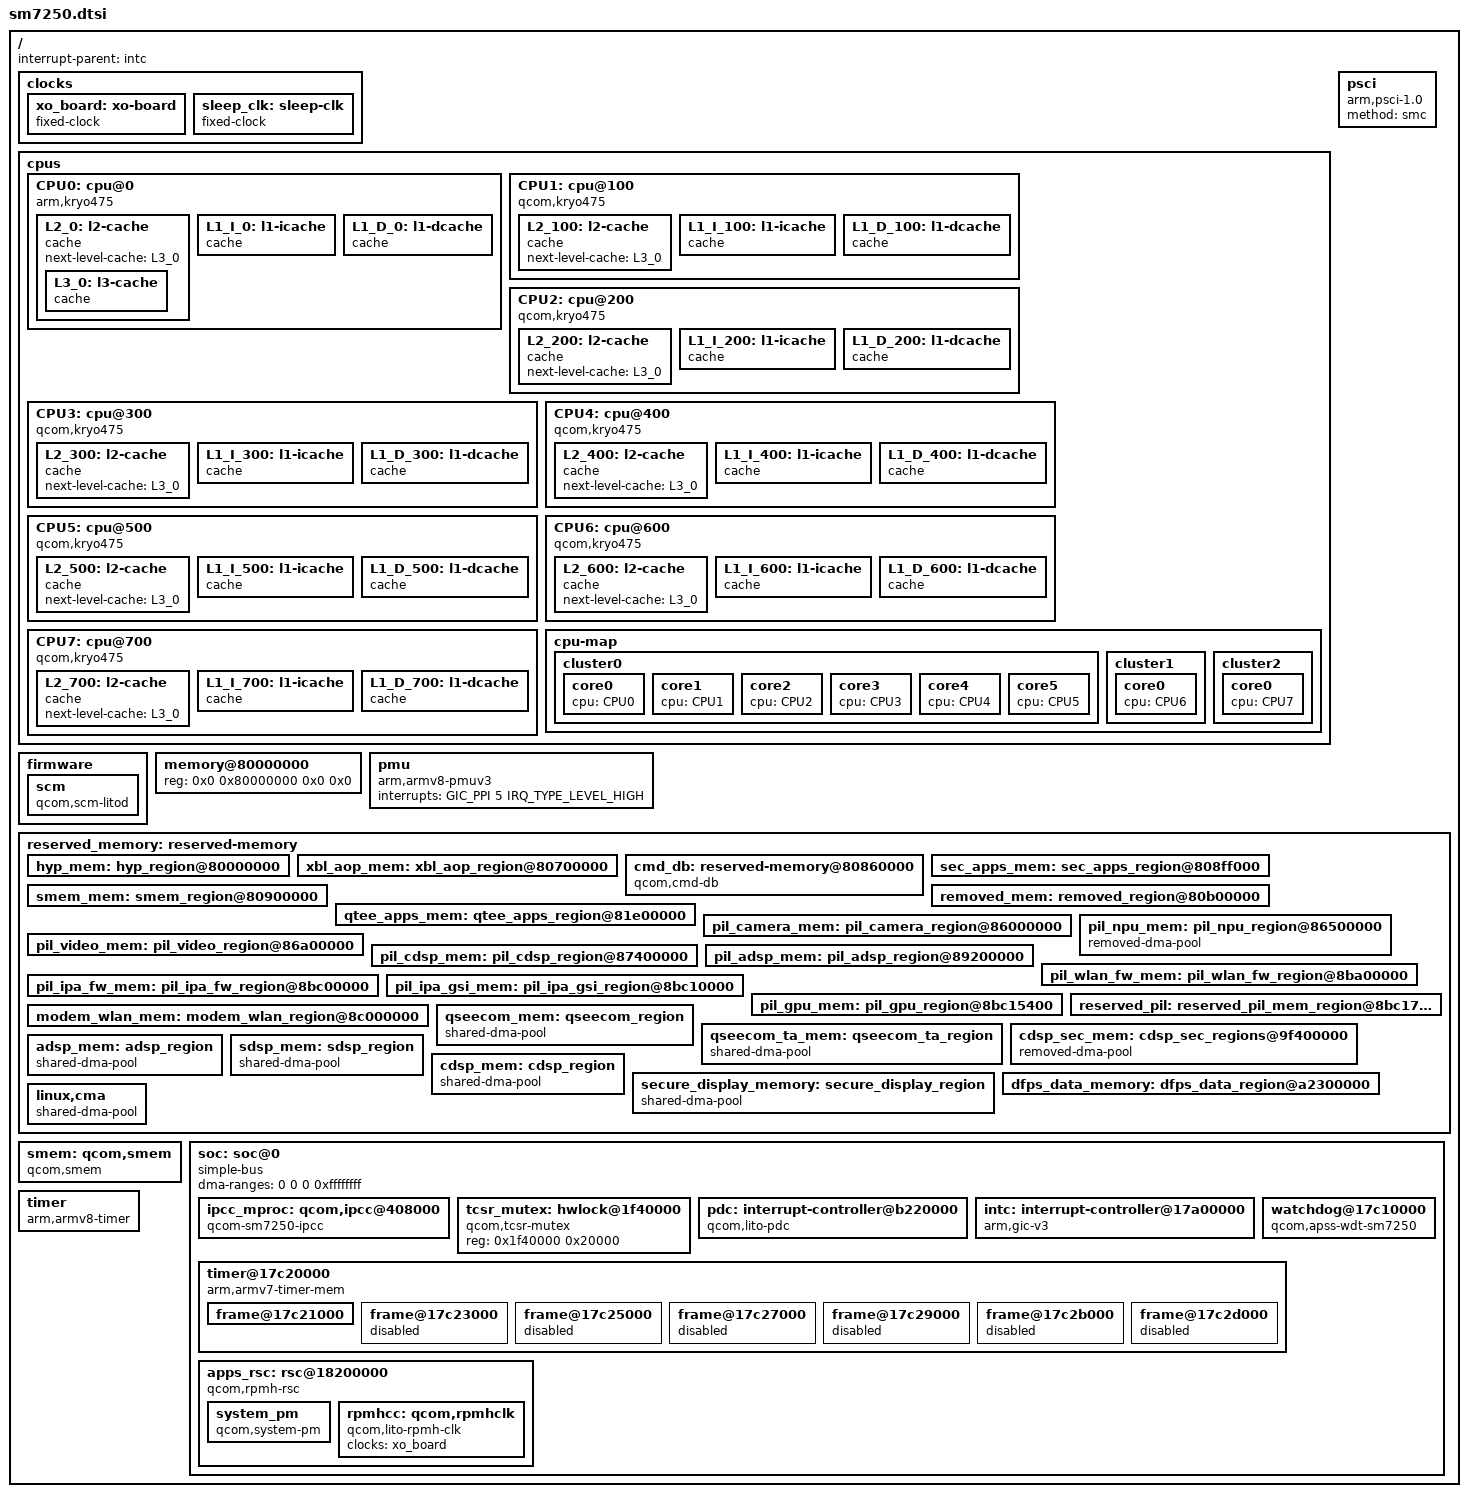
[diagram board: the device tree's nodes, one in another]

// SPDX-License-Identifier: BSD-3-Clause
/*
 */

#include <dt-bindings/clock/qcom,gcc-sm7250.h>
#include <dt-bindings/clock/qcom,rpmh.h>
#include <dt-bindings/gpio/gpio.h>
#include <dt-bindings/interrupt-controller/arm-gic.h>
#include <dt-bindings/mailbox/qcom-ipcc.h>
#include <dt-bindings/soc/qcom,rpmh-rsc.h>

/ {
	interrupt-parent = <&intc>;
	#address-cells = <2>;
	#size-cells = <2>;
	clocks {
		xo_board: xo-board {
			compatible = "fixed-clock";
			clock-frequency = <38400000>;
			clock-output-names = "xo_board";
			#clock-cells = <0>;
		};

		sleep_clk: sleep-clk {
			compatible = "fixed-clock";
			clock-output-names = "chip_sleep_clk";
			clock-frequency = <32000>;
			#clock-cells = <0>;
		};
	};
	cpus {
		#address-cells = <2>;
		#size-cells = <0>;

		CPU0: cpu@0 {
			device_type = "cpu";
			compatible = "arm,kryo475";
			reg = <0x0 0x0>;
			enable-method = "psci";
			capacity-dmips-mhz = <488>;
			dynamic-power-coefficient = <166>;
			next-level-cache = <&L2_0>;
			#cooling-cells = <2>;
			L2_0: l2-cache {
			      compatible = "cache";
			      next-level-cache = <&L3_0>;
				L3_0: l3-cache {
				      compatible = "cache";
				};
			};

			L1_I_0: l1-icache {
				compatible = "cache";
			};

			L1_D_0: l1-dcache {
				compatible = "cache";
			};

		};

		CPU1: cpu@100 {
			device_type = "cpu";
			compatible = "qcom,kryo475";
			reg = <0x0 0x100>;
			enable-method = "psci";
			capacity-dmips-mhz = <488>;
			dynamic-power-coefficient = <166>;
			next-level-cache = <&L2_100>;
			L2_100: l2-cache {
				compatible = "cache";
				next-level-cache = <&L3_0>;
			};

			L1_I_100: l1-icache {
				compatible = "cache";
			};

			L1_D_100: l1-dcache {
				compatible = "cache";
			};

		};

		CPU2: cpu@200 {
			device_type = "cpu";
			compatible = "qcom,kryo475";
			reg = <0x0 0x200>;
			enable-method = "psci";
			capacity-dmips-mhz = <488>;
			dynamic-power-coefficient = <166>;
			next-level-cache = <&L2_200>;
			L2_200: l2-cache {
				compatible = "cache";
				next-level-cache = <&L3_0>;
			};

			L1_I_200: l1-icache {
				compatible = "cache";
			};

			L1_D_200: l1-dcache {
				compatible = "cache";
			};

		};

		CPU3: cpu@300 {
			device_type = "cpu";
			compatible = "qcom,kryo475";
			reg = <0x0 0x300>;
			enable-method = "psci";
			capacity-dmips-mhz = <488>;
			dynamic-power-coefficient = <166>;
			next-level-cache = <&L2_300>;
			L2_300: l2-cache {
				compatible = "cache";
				next-level-cache = <&L3_0>;
			};

			L1_I_300: l1-icache {
				compatible = "cache";
			};

			L1_D_300: l1-dcache {
				compatible = "cache";
			};

		};

		CPU4: cpu@400 {
			device_type = "cpu";
			compatible = "qcom,kryo475";
			reg = <0x0 0x400>;
			enable-method = "psci";
			capacity-dmips-mhz = <488>;
			dynamic-power-coefficient = <166>;
			next-level-cache = <&L2_400>;
			L2_400: l2-cache {
				compatible = "cache";
				next-level-cache = <&L3_0>;
			};

			L1_I_400: l1-icache {
				compatible = "cache";
			};

			L1_D_400: l1-dcache {
				compatible = "cache";
			};
		};

		CPU5: cpu@500 {
			device_type = "cpu";
			compatible = "qcom,kryo475";
			reg = <0x0 0x500>;
			enable-method = "psci";
			capacity-dmips-mhz = <488>;
			dynamic-power-coefficient = <166>;
			next-level-cache = <&L2_500>;
			L2_500: l2-cache {
				compatible = "cache";
				next-level-cache = <&L3_0>;
			};

			L1_I_500: l1-icache {
				compatible = "cache";
			};

			L1_D_500: l1-dcache {
				compatible = "cache";
			};
		};

		CPU6: cpu@600 {
			device_type = "cpu";
			compatible = "qcom,kryo475";
			reg = <0x0 0x600>;
			enable-method = "psci";
			capacity-dmips-mhz = <1024>;
			dynamic-power-coefficient = <393>;
			next-level-cache = <&L2_600>;
			#cooling-cells = <2>;
			L2_600: l2-cache {
				compatible = "cache";
				next-level-cache = <&L3_0>;
			};

			L1_I_600: l1-icache {
				compatible = "cache";
			};

			L1_D_600: l1-dcache {
				compatible = "cache";
			};

		};

		CPU7: cpu@700 {
			device_type = "cpu";
			compatible = "qcom,kryo475";
			reg = <0x0 0x700>;
			enable-method = "psci";
			capacity-dmips-mhz = <1024>;
			dynamic-power-coefficient = <428>;
			next-level-cache = <&L2_700>;
			#cooling-cells = <2>;
			L2_700: l2-cache {
				compatible = "cache";
				next-level-cache = <&L3_0>;
			};

			L1_I_700: l1-icache {
				compatible = "cache";
			};

			L1_D_700: l1-dcache {
				compatible = "cache";
			};
		};
		cpu-map {
			cluster0 {
				core0 {
					cpu = <&CPU0>;
				};

				core1 {
					cpu = <&CPU1>;
				};

				core2 {
					cpu = <&CPU2>;
				};

				core3 {
					cpu = <&CPU3>;
				};

				core4 {
					cpu = <&CPU4>;
				};

				core5 {
					cpu = <&CPU5>;
				};
			};

			cluster1 {
				core0 {
					cpu = <&CPU6>;
				};
			};

			cluster2 {
				core0 {
					cpu = <&CPU7>;
				};
			};
		};
	};
	firmware {
		scm: scm {
			compatible = "qcom,scm-litod", "qcom,scm";
			#reset-cells = <1>;
		};
	};
	memory@80000000 {
		device_type = "memory";
		/* We expect the bootloader to fill in the size */
		reg = <0x0 0x80000000 0x0 0x0>;
	};
	pmu {
                compatible = "arm,armv8-pmuv3";
                interrupts = <GIC_PPI 5 IRQ_TYPE_LEVEL_HIGH>;
        };
	psci {
	compatible = "arm,psci-1.0";
	method = "smc";
	};
	reserved_memory: reserved-memory {
		#address-cells = <2>;
		#size-cells = <2>;
		ranges;

		hyp_mem: hyp_region@80000000 {
			reg = <0x0 0x80000000 0x0 0x600000>;
			no-map;
		};

		xbl_aop_mem: xbl_aop_region@80700000 {
			reg = <0x0 0x80700000 0x0 0x160000>;
			no-map;
		};

		cmd_db: reserved-memory@80860000 {
			compatible = "qcom,cmd-db";
			reg = <0x0 0x80860000 0x0 0x20000>;
			no-map;
		};

		sec_apps_mem: sec_apps_region@808ff000 {
			reg = <0x0 0x808ff000 0x0 0x1000>;
			no-map;
		};

		smem_mem: smem_region@80900000 {
			reg = <0x0 0x80900000 0x0 0x200000>;
			no-map;
		};

		removed_mem: removed_region@80b00000 {
			reg = <0x0 0x80b00000 0x0 0x1300000>;
			no-map;
		};

		qtee_apps_mem: qtee_apps_region@81e00000 {
			reg = <0x0 0x81e00000 0x0 0x4200000>;
			no-map;
		};

		pil_camera_mem: pil_camera_region@86000000 {
			reg = <0x0 0x86000000 0x0 0x500000>;
			no-map;
		};

		pil_npu_mem: pil_npu_region@86500000 {
			compatible = "removed-dma-pool";
			no-map;
			reg = <0x0 0x86500000 0x0 0x500000>;
		};

		pil_video_mem: pil_video_region@86a00000 {
			reg = <0x0 0x86a00000 0x0 0x500000>;
			no-map;
		};

		pil_cdsp_mem: pil_cdsp_region@87400000 {
			reg = <0x0 0x87400000 0x0 0x1e00000>;
			no-map;
		};

		pil_adsp_mem: pil_adsp_region@89200000 {
			reg = <0x0 0x89200000 0x0 0x2800000>;
			no-map;
		};

		pil_wlan_fw_mem: pil_wlan_fw_region@8ba00000 {
			reg = <0x0 0x8ba00000 0x0 0x200000>;
			no-map;
		};

		pil_ipa_fw_mem: pil_ipa_fw_region@8bc00000 {
			reg = <0x0 0x8bc00000 0x0 0x10000>;
			no-map;
		};

		pil_ipa_gsi_mem: pil_ipa_gsi_region@8bc10000 {
			reg = <0x0 0x8bc10000 0x0 0x5400>;
			no-map;
		};

		pil_gpu_mem: pil_gpu_region@8bc15400 {
			reg = <0x0 0x8bc15400 0x0 0x2000>;
			no-map;
		};

		reserved_pil: reserved_pil_mem_region@8bc17400 {
			reg = <0x0 0x8bc17400 0x0 0x3e8c00>;
			no-map;
		};

		modem_wlan_mem: modem_wlan_region@8c000000 {
			reg = <0x0 0x8c000000 0x0 0xf800000>;
			no-map;
		};

		qseecom_mem: qseecom_region {
			compatible = "shared-dma-pool";
			alloc-ranges = <0x0 0x00000000 0x0 0xffffffff>;
			reusable;
			alignment = <0x0 0x400000>;
			size = <0x0 0x1400000>;
		};

		qseecom_ta_mem: qseecom_ta_region {
			compatible = "shared-dma-pool";
			alloc-ranges = <0x0 0x00000000 0x0 0xffffffff>;
			reusable;
			alignment = <0x0 0x400000>;
			size = <0x0 0x1000000>;
		};

		cdsp_sec_mem: cdsp_sec_regions@9f400000 {
			compatible = "removed-dma-pool";
			no-map;
			reg = <0x0 0x9f400000 0x0 0xc00000>;
		};

		adsp_mem: adsp_region {
			compatible = "shared-dma-pool";
			alloc-ranges = <0x0 0x00000000 0x0 0xffffffff>;
			reusable;
			alignment = <0x0 0x400000>;
			size = <0x0 0xC00000>;
		};

		sdsp_mem: sdsp_region {
			compatible = "shared-dma-pool";
			alloc-ranges = <0x0 0x00000000 0x0 0xffffffff>;
			reusable;
			alignment = <0x0 0x400000>;
			size = <0x0 0x400000>;
		};

		cdsp_mem: cdsp_region {
			compatible = "shared-dma-pool";
			alloc-ranges = <0x0 0x00000000 0x0 0xffffffff>;
			reusable;
			alignment = <0x0 0x400000>;
			size = <0x0 0x400000>;
		};

		secure_display_memory: secure_display_region { /* Secure UI */
			compatible = "shared-dma-pool";
			alloc-ranges = <0x0 0x00000000 0x0 0xffffffff>;
			reusable;
			alignment = <0x0 0x400000>;
			size = <0x0 0xA000000>;
		};

		dfps_data_memory: dfps_data_region@a2300000 {
			reg = <0x0 0xa2300000 0x0 0x0100000>;
			label = "dfps_data_region";
		};

		/* global autoconfigured region for contiguous allocations */
		linux,cma {
			compatible = "shared-dma-pool";
			alloc-ranges = <0x0 0x00000000 0x0 0xffffffff>;
			reusable;
			alignment = <0x0 0x400000>;
			size = <0x0 0x2000000>;
			linux,cma-default;
		};

	};
	smem: qcom,smem {
		compatible = "qcom,smem";
		memory-region = <&smem_mem>;
		hwlocks = <&tcsr_mutex 3>;
	};
	soc: soc@0 {
		#address-cells = <1>;
		#size-cells = <1>;
		ranges = <0 0 0 0xffffffff>;
		dma-ranges = <0 0 0 0xffffffff>;
		compatible = "simple-bus";

		ipcc_mproc: qcom,ipcc@408000 {
			compatible = "qcom-sm7250-ipcc", "qcom,ipcc";
			reg = <0x408000 0x1000>;
			interrupts = <GIC_SPI 229 IRQ_TYPE_LEVEL_HIGH>;
			interrupt-controller;
			#interrupt-cells = <3>;
			#mbox-cells = <2>;
		};
		tcsr_mutex: hwlock@1f40000 {
			compatible = "qcom,tcsr-mutex";
			reg = <0x1f40000 0x20000>;
			#hwlock-cells = <1>;
		};
		
		pdc: interrupt-controller@b220000 {
			compatible = "qcom,lito-pdc", "qcom,pdc";
			reg = <0xb220000 0x30000>, <0x17c000f0 0x60>;
			qcom,pdc-ranges = <0 480 42>, <42 612 28>, <70 63 1>,
				  <71 640 15>, <86 522 52>;
			#interrupt-cells = <2>;
			interrupt-parent = <&intc>;
			interrupt-controller;
		};
		intc: interrupt-controller@17a00000 {
			compatible = "arm,gic-v3";
			#interrupt-cells = <3>;
			interrupt-controller;
			reg = <0x17a00000 0x10000>,	/* GICD */
			      <0x17a60000 0x100000>;	/* GICR * 8 */
			interrupts = <GIC_PPI 8 IRQ_TYPE_LEVEL_HIGH>;
		};
		watchdog@17c10000 {
			compatible = "qcom,apss-wdt-sm7250", "qcom,kpss-wdt";
			reg = <0 0x17c10000 0 0x1000>;
			clocks = <&sleep_clk>;
			interrupts = <GIC_SPI 0 IRQ_TYPE_LEVEL_HIGH>;
		};	
		timer@17c20000 {
			compatible = "arm,armv7-timer-mem";
			reg = <0x17c20000 0x1000>;
			clock-frequency = <19200000>;
			#address-cells = <1>;
			#size-cells = <1>;
			ranges;

			frame@17c21000 {
				frame-number = <0>;
				interrupts = <GIC_SPI 8 IRQ_TYPE_LEVEL_HIGH>,
					     <GIC_SPI 6 IRQ_TYPE_LEVEL_HIGH>;
				reg = <0x17c21000 0x1000>,
				      <0x17c22000 0x1000>;
			};

			frame@17c23000 {
				frame-number = <1>;
				interrupts = <GIC_SPI 9 IRQ_TYPE_LEVEL_HIGH>;
				reg = <0x17c23000 0x1000>;
				status = "disabled";
			};

			frame@17c25000 {
				frame-number = <2>;
				interrupts = <GIC_SPI 10 IRQ_TYPE_LEVEL_HIGH>;
				reg = <0x17c25000 0x1000>;
				status = "disabled";
			};

			frame@17c27000 {
				frame-number = <3>;
				interrupts = <GIC_SPI 11 IRQ_TYPE_LEVEL_HIGH>;
				reg = <0x17c27000 0x1000>;
				status = "disabled";
			};

			frame@17c29000 {
				frame-number = <4>;
				interrupts = <GIC_SPI 12 IRQ_TYPE_LEVEL_HIGH>;
				reg = <0x17c29000 0x1000>;
				status = "disabled";
			};

			frame@17c2b000 {
				frame-number = <5>;
				interrupts = <GIC_SPI 13 IRQ_TYPE_LEVEL_HIGH>;
				reg = <0x17c2b000 0x1000>;
				status = "disabled";
			};

			frame@17c2d000 {
				frame-number = <6>;
				interrupts = <GIC_SPI 14 IRQ_TYPE_LEVEL_HIGH>;
				reg = <0x17c2d000 0x1000>;
				status = "disabled";
			};
		};
		apps_rsc: rsc@18200000 {
			compatible = "qcom,rpmh-rsc";
			label = "apps_rsc";
			reg = <0x18200000 0x10000>,
				<0x18210000 0x10000>,
				<0x18220000 0x10000>;
			reg-names = "drv-0", "drv-1", "drv-2";
			interrupts = <GIC_SPI 3 IRQ_TYPE_LEVEL_HIGH>,
				     <GIC_SPI 4 IRQ_TYPE_LEVEL_HIGH>,
				     <GIC_SPI 5 IRQ_TYPE_LEVEL_HIGH>;
			qcom,tcs-offset = <0xd00>;
			qcom,drv-id = <2>;
			qcom,tcs-config = <ACTIVE_TCS 2>, <SLEEP_TCS 3>,
					  <WAKE_TCS 3>, <CONTROL_TCS 1>;
			#address-cells = <1>;
			#size-cells = <1>;
			ranges;
			system_pm {
				compatible = "qcom,system-pm";
			};

			rpmhcc: qcom,rpmhclk {
				compatible = "qcom,lito-rpmh-clk";
				#clock-cells = <1>;
				clock-names = "xo";
				clocks = <&xo_board>;
			};
		};
	};
	timer {
		compatible = "arm,armv8-timer";
		interrupts = <GIC_PPI 1 (GIC_CPU_MASK_SIMPLE(8) | IRQ_TYPE_LEVEL_LOW)>,
			     <GIC_PPI 2 (GIC_CPU_MASK_SIMPLE(8) | IRQ_TYPE_LEVEL_LOW)>,
			     <GIC_PPI 3 (GIC_CPU_MASK_SIMPLE(8) | IRQ_TYPE_LEVEL_LOW)>,
			     <GIC_PPI 0 (GIC_CPU_MASK_SIMPLE(8) | IRQ_TYPE_LEVEL_LOW)>;
		clock-frequency = <19200000>;
	};
};
